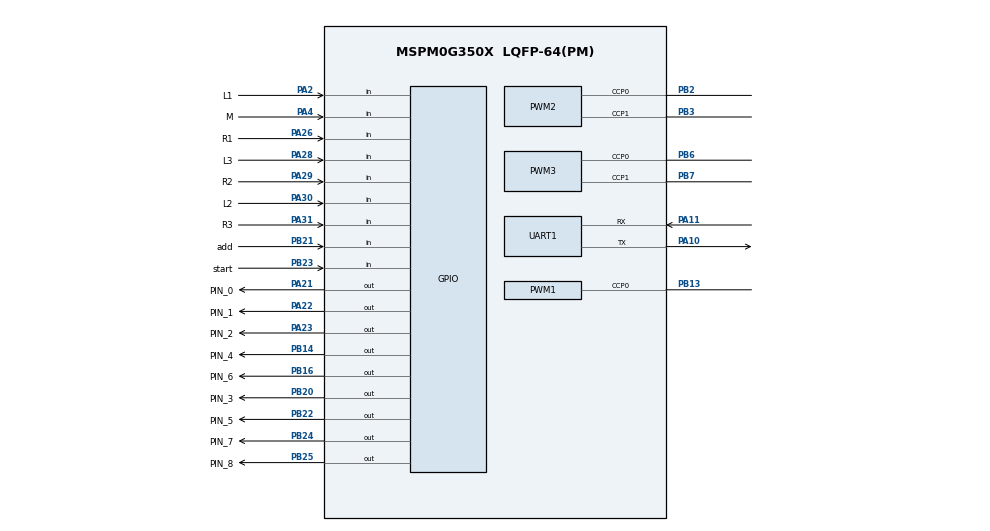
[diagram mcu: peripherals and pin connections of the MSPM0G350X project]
/**
 * @cliArgs --device "MSPM0G350X" --package "LQFP-64(PM)" --part "Default" --product "mspm0_sdk@2.01.00.03"
 * @versions {"tool":"1.20.0+3587"}
 */

/**
 * Import the modules used in this configuration.
 */
const DMA           = scripting.addModule("/ti/driverlib/DMA");
const GPIO          = scripting.addModule("/ti/driverlib/GPIO", {}, false);
const GPIO1         = GPIO.addInstance();
const GPIO2         = GPIO.addInstance();
const GPIO3         = GPIO.addInstance();
const GPIO4         = GPIO.addInstance();
const GPIO5         = GPIO.addInstance();
const GPIO6         = GPIO.addInstance();
const GPIO7         = GPIO.addInstance();
const PWM           = scripting.addModule("/ti/driverlib/PWM", {}, false);
const PWM1          = PWM.addInstance();
const PWM2          = PWM.addInstance();
const PWM3          = PWM.addInstance();
const SYSCTL        = scripting.addModule("/ti/driverlib/SYSCTL");
const UART          = scripting.addModule("/ti/driverlib/UART", {}, false);
const UART1         = UART.addInstance();
const UART2         = UART.addInstance();
const ProjectConfig = scripting.addModule("/ti/project_config/ProjectConfig");

/**
 * Write custom configuration values to the imported modules.
 */
const Board = scripting.addModule("/ti/driverlib/Board", {}, false);

GPIO1.$name                          = "GPIO_OLED";
GPIO1.associatedPins.create(2);
GPIO1.associatedPins[0].$name        = "PIN_SCL";
GPIO1.associatedPins[0].assignedPort = "PORTA";
GPIO1.associatedPins[0].assignedPin  = "17";
GPIO1.associatedPins[1].$name        = "PIN_SDA";
GPIO1.associatedPins[1].assignedPort = "PORTB";
GPIO1.associatedPins[1].assignedPin  = "15";

GPIO2.port                          = "PORTA";
GPIO2.$name                         = "GPIO_motor1_dir";
GPIO2.associatedPins.create(3);
GPIO2.associatedPins[0].$name       = "PIN_0";
GPIO2.associatedPins[0].pin.$assign = "PA21";
GPIO2.associatedPins[1].$name       = "PIN_1";
GPIO2.associatedPins[1].pin.$assign = "PA22";
GPIO2.associatedPins[2].$name       = "PIN_2";
GPIO2.associatedPins[2].pin.$assign = "PA23";

GPIO3.$name                         = "GPIO_motor2_dir";
GPIO3.associatedPins.create(5);
GPIO3.associatedPins[0].$name       = "PIN_3";
GPIO3.associatedPins[0].pin.$assign = "PB20";
GPIO3.associatedPins[1].$name       = "PIN_4";
GPIO3.associatedPins[1].pin.$assign = "PB14";
GPIO3.associatedPins[2].$name       = "PIN_5";
GPIO3.associatedPins[2].pin.$assign = "PB22";
GPIO3.associatedPins[3].$name       = "PIN_6";
GPIO3.associatedPins[3].pin.$assign = "PB16";
GPIO3.associatedPins[4].$name       = "PIN_7";
GPIO3.associatedPins[4].pin.$assign = "PB24";

GPIO4.$name                              = "GPIO_scare";
GPIO4.associatedPins.create(7);
GPIO4.associatedPins[0].$name            = "L3";
GPIO4.associatedPins[0].direction        = "INPUT";
GPIO4.associatedPins[0].internalResistor = "PULL_UP";
GPIO4.associatedPins[0].pin.$assign      = "PA28";
GPIO4.associatedPins[1].$name            = "L2";
GPIO4.associatedPins[1].direction        = "INPUT";
GPIO4.associatedPins[1].internalResistor = "PULL_UP";
GPIO4.associatedPins[1].pin.$assign      = "PA30";
GPIO4.associatedPins[2].$name            = "L1";
GPIO4.associatedPins[2].direction        = "INPUT";
GPIO4.associatedPins[2].internalResistor = "PULL_UP";
GPIO4.associatedPins[2].pin.$assign      = "PA2";
GPIO4.associatedPins[3].$name            = "M";
GPIO4.associatedPins[3].direction        = "INPUT";
GPIO4.associatedPins[3].internalResistor = "PULL_UP";
GPIO4.associatedPins[3].pin.$assign      = "PA4";
GPIO4.associatedPins[4].$name            = "R1";
GPIO4.associatedPins[4].direction        = "INPUT";
GPIO4.associatedPins[4].internalResistor = "PULL_UP";
GPIO4.associatedPins[4].pin.$assign      = "PA26";
GPIO4.associatedPins[5].$name            = "R2";
GPIO4.associatedPins[5].direction        = "INPUT";
GPIO4.associatedPins[5].internalResistor = "PULL_UP";
GPIO4.associatedPins[5].pin.$assign      = "PA29";
GPIO4.associatedPins[6].$name            = "R3";
GPIO4.associatedPins[6].direction        = "INPUT";
GPIO4.associatedPins[6].internalResistor = "PULL_UP";
GPIO4.associatedPins[6].pin.$assign      = "PA31";

GPIO5.$name                          = "beep";
GPIO5.port                           = "PORTB";
GPIO5.associatedPins[0].$name        = "PIN_8";
GPIO5.associatedPins[0].initialValue = "SET";
GPIO5.associatedPins[0].pin.$assign  = "PB25";

GPIO6.$name                   = "LED";
GPIO6.port                    = "PORTA";
GPIO6.associatedPins[0].$name = "led";

GPIO7.$name                              = "choosemode";
GPIO7.port                               = "PORTB";
GPIO7.associatedPins.create(2);
GPIO7.associatedPins[0].$name            = "add";
GPIO7.associatedPins[0].direction        = "INPUT";
GPIO7.associatedPins[0].internalResistor = "PULL_UP";
GPIO7.associatedPins[0].pin.$assign      = "PB21";
GPIO7.associatedPins[1].$name            = "start";
GPIO7.associatedPins[1].direction        = "INPUT";
GPIO7.associatedPins[1].internalResistor = "PULL_UP";
GPIO7.associatedPins[1].pin.$assign      = "PB23";

PWM1.timerCount                         = 640000;
PWM1.$name                              = "PWM_sensor";
PWM1.ccIndex                            = [0];
PWM1.peripheral.$assign                 = "TIMG12";
PWM1.peripheral.ccp0Pin.$assign         = "PB13";
PWM1.PWM_CHANNEL_0.$name                = "ti_driverlib_pwm_PWMTimerCC0";
PWM1.PWM_CHANNEL_0.dutyCycle            = 10;
PWM1.ccp0PinConfig.direction            = scripting.forceWrite("OUTPUT");
PWM1.ccp0PinConfig.hideOutputInversion  = scripting.forceWrite(false);
PWM1.ccp0PinConfig.onlyInternalResistor = scripting.forceWrite(false);
PWM1.ccp0PinConfig.passedPeripheralType = scripting.forceWrite("Digital");
PWM1.ccp0PinConfig.$name                = "ti_driverlib_gpio_GPIOPinGeneric2";

PWM2.timerCount                         = 16000;
PWM2.$name                              = "PWM_enconder";
PWM2.peripheral.$assign                 = "TIMA1";
PWM2.peripheral.ccp0Pin.$assign         = "PB2";
PWM2.peripheral.ccp1Pin.$assign         = "PB3";
PWM2.PWM_CHANNEL_0.$name                = "ti_driverlib_pwm_PWMTimerCC1";
PWM2.PWM_CHANNEL_0.dutyCycle            = 50;
PWM2.PWM_CHANNEL_1.$name                = "ti_driverlib_pwm_PWMTimerCC2";
PWM2.ccp0PinConfig.direction            = scripting.forceWrite("OUTPUT");
PWM2.ccp0PinConfig.hideOutputInversion  = scripting.forceWrite(false);
PWM2.ccp0PinConfig.onlyInternalResistor = scripting.forceWrite(false);
PWM2.ccp0PinConfig.passedPeripheralType = scripting.forceWrite("Digital");
PWM2.ccp0PinConfig.$name                = "ti_driverlib_gpio_GPIOPinGeneric3";
PWM2.ccp1PinConfig.direction            = scripting.forceWrite("OUTPUT");
PWM2.ccp1PinConfig.hideOutputInversion  = scripting.forceWrite(false);
PWM2.ccp1PinConfig.onlyInternalResistor = scripting.forceWrite(false);
PWM2.ccp1PinConfig.passedPeripheralType = scripting.forceWrite("Digital");
PWM2.ccp1PinConfig.$name                = "ti_driverlib_gpio_GPIOPinGeneric4";

PWM3.timerCount                         = 16000;
PWM3.$name                              = "PWM_frontencoder";
PWM3.peripheral.$assign                 = "TIMG6";
PWM3.peripheral.ccp0Pin.$assign         = "PB6";
PWM3.peripheral.ccp1Pin.$assign         = "PB7";
PWM3.PWM_CHANNEL_0.$name                = "ti_driverlib_pwm_PWMTimerCC3";
PWM3.PWM_CHANNEL_0.dutyCycle            = 50;
PWM3.PWM_CHANNEL_1.$name                = "ti_driverlib_pwm_PWMTimerCC4";
PWM3.PWM_CHANNEL_1.ccValue              = 8000;
PWM3.PWM_CHANNEL_1.dutyCycle            = 50;
PWM3.ccp0PinConfig.direction            = scripting.forceWrite("OUTPUT");
PWM3.ccp0PinConfig.hideOutputInversion  = scripting.forceWrite(false);
PWM3.ccp0PinConfig.onlyInternalResistor = scripting.forceWrite(false);
PWM3.ccp0PinConfig.passedPeripheralType = scripting.forceWrite("Digital");
PWM3.ccp0PinConfig.$name                = "ti_driverlib_gpio_GPIOPinGeneric5";
PWM3.ccp1PinConfig.direction            = scripting.forceWrite("OUTPUT");
PWM3.ccp1PinConfig.hideOutputInversion  = scripting.forceWrite(false);
PWM3.ccp1PinConfig.onlyInternalResistor = scripting.forceWrite(false);
PWM3.ccp1PinConfig.passedPeripheralType = scripting.forceWrite("Digital");
PWM3.ccp1PinConfig.$name                = "ti_driverlib_gpio_GPIOPinGeneric6";

SYSCTL.forceDefaultClkConfig = true;
SYSCTL.clockTreeEn           = true;

UART1.$name                    = "UART_0";
UART1.enabledInterrupts        = ["RX"];
UART1.targetBaudRate           = 115200;
UART1.interruptPriority        = "0";
UART1.peripheral.rxPin.$assign = "PA11";
UART1.peripheral.txPin.$assign = "PA10";
UART1.txPinConfig.$name        = "ti_driverlib_gpio_GPIOPinGeneric0";
UART1.rxPinConfig.$name        = "ti_driverlib_gpio_GPIOPinGeneric1";

UART2.$name             = "UART_1";
UART2.enabledInterrupts = ["RX"];
UART2.interruptPriority = "3";
UART2.txPinConfig.$name = "ti_driverlib_gpio_GPIOPinGeneric7";
UART2.rxPinConfig.$name = "ti_driverlib_gpio_GPIOPinGeneric8";

ProjectConfig.deviceSpin = "MSPM0G3507";
scripting.suppress("Migrating requires going through the Switch Board or Device menu in the Device View section\\.", ProjectConfig, "deviceSpin");

/**
 * Pinmux solution for unlocked pins/peripherals. This ensures that minor changes to the automatic solver in a future
 * version of the tool will not impact the pinmux you originally saw.  These lines can be completely deleted in order to
 * re-solve from scratch.
 */
Board.peripheral.$suggestSolution            = "DEBUGSS";
Board.peripheral.swclkPin.$suggestSolution   = "PA20";
Board.peripheral.swdioPin.$suggestSolution   = "PA19";
GPIO1.associatedPins[0].pin.$suggestSolution = "PA17";
GPIO1.associatedPins[1].pin.$suggestSolution = "PB15";
GPIO6.associatedPins[0].pin.$suggestSolution = "PA12";
UART1.peripheral.$suggestSolution            = "UART0";
UART2.peripheral.$suggestSolution            = "UART1";
UART2.peripheral.rxPin.$suggestSolution      = "PA18";
UART2.peripheral.txPin.$suggestSolution      = "PA8";
